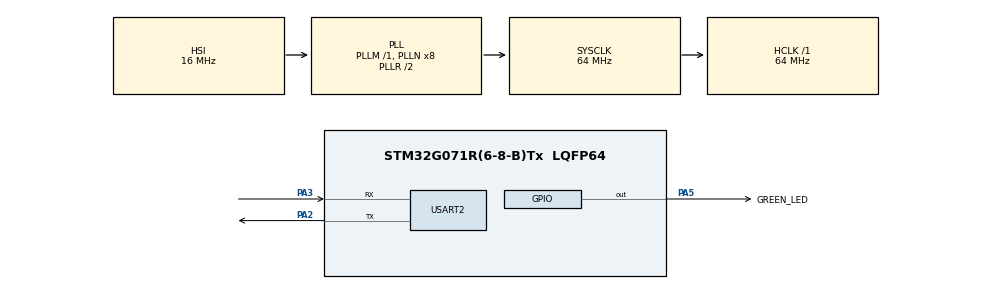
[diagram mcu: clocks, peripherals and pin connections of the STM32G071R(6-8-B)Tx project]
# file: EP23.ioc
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Mcu.Family=STM32G0
Mcu.Name=STM32G071R(6-8-B)Tx
Mcu.Package=LQFP64
PA2.Mode=Asynchronous
PA2.Signal=USART2_TX
PA3.Mode=Asynchronous
PA3.Signal=USART2_RX
PA5.GPIO_Label=GREEN_LED
PA5.Signal=GPIO_Output
PC13.Mode=SYS_WakeUp1
PC13.Signal=SYS_WKUP2
ProjectManager.HeapSize=0x200
ProjectManager.StackSize=0x400
ProjectManager.TargetToolchain=STM32CubeIDE
RCC.ADCFreq_Value=64000000
RCC.AHBFreq_Value=64000000
RCC.CortexFreq_Value=64000000
RCC.EXTERNAL_CLOCK_VALUE=48000
RCC.HCLKFreq_Value=64000000
RCC.HSE_VALUE=8000000
RCC.HSI_VALUE=16000000
RCC.LSE_VALUE=32768
RCC.SYSCLKFreq_VALUE=64000000
RCC.SYSCLKSource=RCC_SYSCLKSOURCE_PLLCLK
RCC.VCOOutputFreq_Value=128000000
USART2.VirtualMode-Asynchronous=VM_ASYNC
board=custom

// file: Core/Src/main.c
/* USER CODE BEGIN Header */
/**
  ******************************************************************************
  * @file           : main.c
  * @brief          : Main program body
  ******************************************************************************
  * @attention
  *
  * Copyright (c) 2025 STMicroelectronics.
  * All rights reserved.
  *
  * This software is licensed under terms that can be found in the LICENSE file
  * in the root directory of this software component.
  * If no LICENSE file comes with this software, it is provided AS-IS.
  *
  ******************************************************************************
  */
/* USER CODE END Header */
#include "main.h"
#include "usart.h"
#include "gpio.h"

/* USER CODE BEGIN PD */
#define USE_STOP_MODE 1
#define USE_STANDBY 1
/* USER CODE END PD */

void SystemClock_Config(void);

int main(void)
{

  /* MCU Configuration--------------------------------------------------------*/

  /* Reset of all peripherals, Initializes the Flash interface and the Systick. */
  HAL_Init();

  /* Configure the system clock */
  SystemClock_Config();

  /* USER CODE BEGIN SysInit */
#ifdef USE_STANDBY
  __HAL_PWR_CLEAR_FLAG(PWR_FLAG_WUF2);
#endif
  /* USER CODE END SysInit */

  /* Initialize all configured peripherals */
  MX_GPIO_Init();
  MX_USART2_UART_Init();
  /* USER CODE BEGIN 2 */
#ifdef USE_SLEEP_MODE
  HAL_SuspendTick();
  HAL_PWR_EnterSLEEPMode(PWR_MAINREGULATOR_ON, PWR_SLEEPENTRY_WFI);
  HAL_ResumeTick();
#endif
  /* USER CODE END 2 */

  /* Infinite loop */
  while (1)
  {

    /* USER CODE BEGIN 3 */
	  HAL_Delay(1000);
#ifdef USE_STOP_MODE
	  HAL_PWR_EnterSTOPMode(PWR_LOWPOWERREGULATOR_ON,PWR_STOPENTRY_WFI);
	  SystemClock_Config();
#endif
#ifdef USE_STANDBY
	  HAL_PWR_EnableWakeUpPin(PWR_WAKEUP_PIN2);
	  HAL_PWR_EnterSTANDBYMode();
#endif
  }
  /* USER CODE END 3 */
}

void SystemClock_Config(void)
{
  RCC_OscInitTypeDef RCC_OscInitStruct = {0};
  RCC_ClkInitTypeDef RCC_ClkInitStruct = {0};

  /** Configure the main internal regulator output voltage
  */
  HAL_PWREx_ControlVoltageScaling(PWR_REGULATOR_VOLTAGE_SCALE1);

  /** Initializes the RCC Oscillators according to the specified parameters
  * in the RCC_OscInitTypeDef structure.
  */
  RCC_OscInitStruct.OscillatorType = RCC_OSCILLATORTYPE_HSI;
  RCC_OscInitStruct.HSIState = RCC_HSI_ON;
  RCC_OscInitStruct.HSIDiv = RCC_HSI_DIV1;
  RCC_OscInitStruct.HSICalibrationValue = RCC_HSICALIBRATION_DEFAULT;
  RCC_OscInitStruct.PLL.PLLState = RCC_PLL_ON;
  RCC_OscInitStruct.PLL.PLLSource = RCC_PLLSOURCE_HSI;
  RCC_OscInitStruct.PLL.PLLM = RCC_PLLM_DIV1;
  RCC_OscInitStruct.PLL.PLLN = 8;
  RCC_OscInitStruct.PLL.PLLP = RCC_PLLP_DIV2;
  RCC_OscInitStruct.PLL.PLLQ = RCC_PLLQ_DIV2;
  RCC_OscInitStruct.PLL.PLLR = RCC_PLLR_DIV2;
  if (HAL_RCC_OscConfig(&RCC_OscInitStruct) != HAL_OK)
  {
    Error_Handler();
  }

  /** Initializes the CPU, AHB and APB buses clocks
  */
  RCC_ClkInitStruct.ClockType = RCC_CLOCKTYPE_HCLK|RCC_CLOCKTYPE_SYSCLK
                              |RCC_CLOCKTYPE_PCLK1;
  RCC_ClkInitStruct.SYSCLKSource = RCC_SYSCLKSOURCE_PLLCLK;
  RCC_ClkInitStruct.AHBCLKDivider = RCC_SYSCLK_DIV1;
  RCC_ClkInitStruct.APB1CLKDivider = RCC_HCLK_DIV1;

  if (HAL_RCC_ClockConfig(&RCC_ClkInitStruct, FLASH_LATENCY_2) != HAL_OK)
  {
    Error_Handler();
  }
}

/* USER CODE BEGIN 4 */
void HAL_GPIO_EXTI_Falling_Callback(uint16_t GPIO_Pin)
{
	HAL_GPIO_TogglePin(GREEN_LED_GPIO_Port, GREEN_LED_Pin);
}
/* USER CODE END 4 */

void Error_Handler(void)
{
  __disable_irq();
  while (1)
  {
  }
}
